# ATSAMD20E16BU device description
Architecture: CORTEX-M0PLUS; Family: SAMD; Series: SAMD20
Registers are 8-bit, read-write, reset 0x0 unless marked. A register's access mark holds for its fields unless they carry their own. Offsets are from the block's base; [hi:lo] are bit positions; {n}, {i} and the like mark numbered series; 'fields as' and 'values as' point back to an identical list; <NAME> marks a mode.

## TC — Basic Timer Counter
Instances: TC{n} {0x42002000+0x400*n} (n=0..5)
Modes: COUNT8 when TC.CTRLA.MODE=1 (8-bit Counter Mode); COUNT16 when TC.CTRLA.MODE=0 (16-bit Counter Mode); COUNT32 when TC.CTRLA.MODE=2 (32-bit Counter Mode)
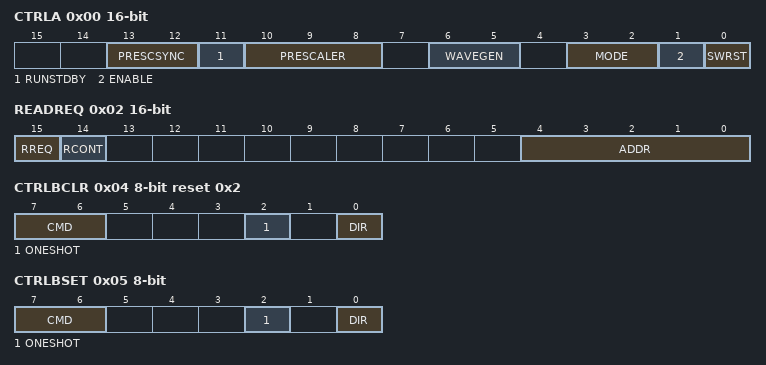
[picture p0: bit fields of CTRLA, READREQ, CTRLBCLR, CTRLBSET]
0x00 CTRLA 16-bit — Control A
  [13:12] PRESCSYNC — Prescaler and Counter Synchronization
    0=GCLK (Reload or reset Counter on next GCLK); 1=PRESC (Reload or reset Counter on next prescaler clock); 2=RESYNC (Reload or reset Counter on next GCLK. Reset prescaler counter)
  [11] RUNSTDBY — Run in Standby
  [10:8] PRESCALER
    0=DIV1 (GCLK_TC); 1=DIV2 (GCLK_TC/2); 2=DIV4 (GCLK_TC/4); 3=DIV8 (GCLK_TC/8); 4=DIV16 (GCLK_TC/16); 5=DIV64 (GCLK_TC/64); 6=DIV256 (GCLK_TC/256); 7=DIV1024 (GCLK_TC/1024)
  [6:5] WAVEGEN — Waveform Generation Operation
    0=NFRQ; 1=MFRQ; 2=NPWM; 3=MPWM
  [3:2] MODE — TC Mode
    0=COUNT16 (Counter in 16-bit mode); 1=COUNT8 (Counter in 8-bit mode); 2=COUNT32 (Counter in 32-bit mode)
  [1] ENABLE
  [0] SWRST — Software Reset
0x02 READREQ 16-bit — Read Request
  [15] RREQ — Read Request
  [14] RCONT — Read Continuously
  [4:0] ADDR — Address
0x04 CTRLBCLR reset 0x2 (atomic clear) — Control B Clear
  [7:6] CMD — Command
    0=NONE (No action); 1=RETRIGGER (Force start, restart or retrigger); 2=STOP (Force stop)
  [2] ONESHOT
  [0] DIR — Counter Direction
0x05 CTRLBSET (atomic set) — Control B Set
  fields as CTRLBCLR
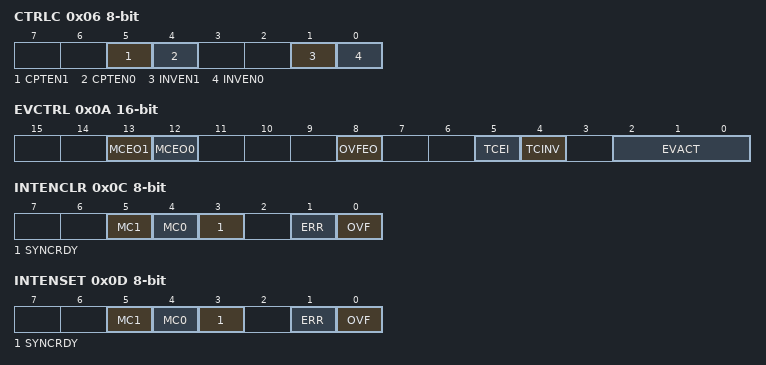
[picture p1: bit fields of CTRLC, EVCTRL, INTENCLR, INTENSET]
0x06 CTRLC — Control C
  [5] CPTEN1 — Capture Channel 1 Enable
  [4] CPTEN0 — Capture Channel 0 Enable
  [1] INVEN1 — Output Waveform 1 Invert Enable
  [0] INVEN0 — Output Waveform 0 Invert Enable
0x08 DBGCTRL — Debug Control
  [0] DBGRUN — Debug Run Mode
0x0A EVCTRL 16-bit — Event Control
  [13] MCEO1 — Match or Capture Channel 1 Event Output Enable
  [12] MCEO0 — Match or Capture Channel 0 Event Output Enable
  [8] OVFEO — Overflow/Underflow Event Output Enable
  [5] TCEI — TC Event Input
  [4] TCINV — TC Inverted Event Input
  [2:0] EVACT — Event Action
    0=OFF (Event action disabled); 1=RETRIGGER (Start, restart or retrigger TC on event); 2=COUNT (Count on event); 3=START (Start TC on event); 5=PPW (Period captured into CC0 Pulse Width in CC1); 6=PWP (Period captured into CC1 Pulse Width on CC0)
0x0C INTENCLR (atomic clear) — Interrupt Enable Clear
  [5] MC1 — Match or Capture Channel 1 Interrupt Enable
  [4] MC0 — Match or Capture Channel 0 Interrupt Enable
  [3] SYNCRDY — Synchronization Ready Interrupt Enable
  [1] ERR — Error Interrupt Enable
  [0] OVF — Overflow Interrupt Enable
0x0D INTENSET (atomic set) — Interrupt Enable Set
  fields as INTENCLR
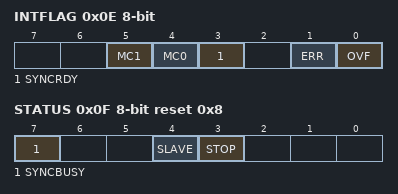
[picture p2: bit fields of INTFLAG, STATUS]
0x0E INTFLAG (atomic clear) — Interrupt Flag Status and Clear
  [5] MC1 — Match or Capture Channel 1
  [4] MC0 — Match or Capture Channel 0
  [3] SYNCRDY — Synchronization Ready
  [1] ERR — Error
  [0] OVF — Overflow
0x0F STATUS ro reset 0x8
  [7] SYNCBUSY — Synchronization Busy
  [4] SLAVE
  [3] STOP
0x10 COUNT <COUNT16> 16-bit — COUNT16 Counter Value
  [15:0] COUNT — Counter Value
{0x18+2i} CC[{i}] (i=0..1) <COUNT16> 16-bit — COUNT16 Compare/Capture
  [15:0] CC — Compare/Capture Value
0x10 COUNT <COUNT32> 32-bit — COUNT32 Counter Value
  [31:0] COUNT — Counter Value
{0x18+4i} CC[{i}] (i=0..1) <COUNT32> 32-bit — COUNT32 Compare/Capture
  [31:0] CC — Compare/Capture Value
0x10 COUNT <COUNT8> — COUNT8 Counter Value
  [7:0] COUNT — Counter Value
0x14 PER <COUNT8> reset 0xFF — COUNT8 Period Value
  [7:0] PER — Period Value
{0x18+i} CC[{i}] (i=0..1) <COUNT8> — COUNT8 Compare/Capture
  [7:0] CC — Compare/Capture Value

## WDT — Watchdog Timer
Instances: WDT 0x40001000
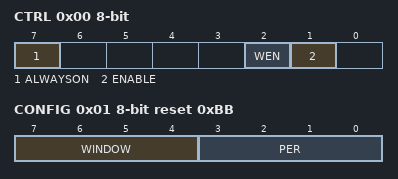
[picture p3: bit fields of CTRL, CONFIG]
0x00 CTRL (WSYNC) — Control
  [7] ALWAYSON
  [2] WEN — Watchdog Timer Window Mode Enable
  [1] ENABLE
0x01 CONFIG reset 0xBB (WSYNC) — Configuration
  [7:4] WINDOW — Window Mode Time-Out Period
    0=8 clock cycles; 1=16 clock cycles; 2=32 clock cycles; 3=64 clock cycles; 4=128 clock cycles; 5=256 clock cycles; 6=512 clock cycles; 7=1K (1024 clock cycles); 8=2K (2048 clock cycles); 9=4K (4096 clock cycles); 10=8K (8192 clock cycles); 11=16K (16384 clock cycles)
  [3:0] PER — Time-Out Period
    values as WINDOW
0x02 EWCTRL reset 0xB — Early Warning Interrupt Control
  [3:0] EWOFFSET — Early Warning Interrupt Time Offset
    values as CONFIG.WINDOW
0x04 INTENCLR (atomic clear) — Interrupt Enable Clear
  [0] EW — Early Warning Interrupt Enable
0x05 INTENSET (atomic set) — Interrupt Enable Set
  [0] EW — Early Warning Interrupt Enable
0x06 INTFLAG (atomic clear) — Interrupt Flag Status and Clear
  [0] EW — Early Warning
0x07 STATUS ro
  [7] SYNCBUSY — Synchronization Busy
0x08 CLEAR wo (WSYNC)
  [7:0] CLEAR — Watchdog Clear
    165=KEY (Clear Key)

## Notices in the file
Copyright (c) 2019 Microchip Technology Inc.
SPDX-License-Identifier: Apache-2.0
Licensed under the Apache License, Version 2.0 (the "License");
you may not use this file except in compliance with the License.
You may obtain a copy of the License at
http://www.apache.org/licenses/LICENSE-2.0
Unless required by applicable law or agreed to in writing, software
distributed under the License is distributed on an "AS IS" BASIS,
WITHOUT WARRANTIES OR CONDITIONS OF ANY KIND, either express or implied.
See the License for the specific language governing permissions and
limitations under the License.
